# MSP430FR5969 register map
Vendor: msp430gen; File version: v0.4.0-24-gb954137
Registers are 16-bit, read-write, reset 0x0 unless marked. A register's access mark holds for its fields unless they carry their own. Offsets are from the block's base; [hi:lo] are bit positions; {n}, {i} and the like mark numbered series.

## PORT_3_4
Base 0x00000220
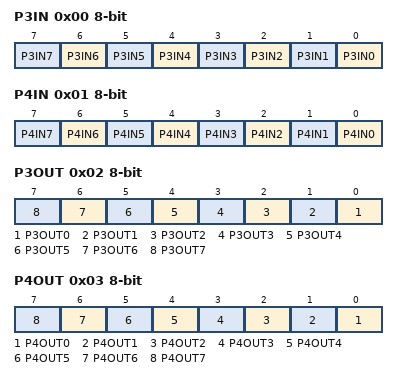
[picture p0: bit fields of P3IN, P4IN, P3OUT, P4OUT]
0x00 P3IN 8-bit — Port 3 Input
  [n] P3IN{n} (n=0..7)
0x01 P4IN 8-bit — Port 4 Input
  [n] P4IN{n} (n=0..7)
0x02 P3OUT 8-bit — Port 3 Output
  [n] P3OUT{n} (n=0..7)
0x03 P4OUT 8-bit — Port 4 Output
  [n] P4OUT{n} (n=0..7)
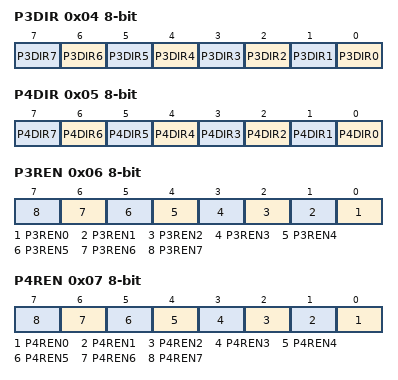
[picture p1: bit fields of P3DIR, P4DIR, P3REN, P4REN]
0x04 P3DIR 8-bit — Port 3 Direction
  [n] P3DIR{n} (n=0..7)
0x05 P4DIR 8-bit — Port 4 Direction
  [n] P4DIR{n} (n=0..7)
0x06 P3REN 8-bit — Port 3 Resistor Enable
  [n] P3REN{n} (n=0..7)
0x07 P4REN 8-bit — Port 4 Resistor Enable
  [n] P4REN{n} (n=0..7)
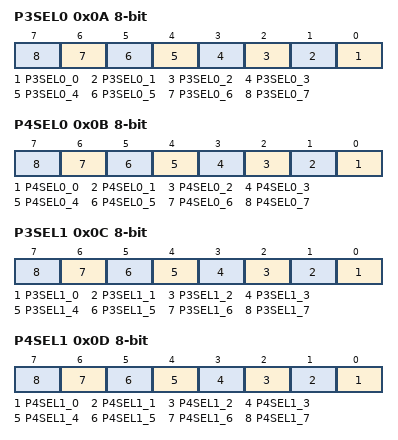
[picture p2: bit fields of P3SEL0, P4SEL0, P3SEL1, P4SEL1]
0x0A P3SEL0 8-bit — Port 3 Selection 0
  [n] P3SEL0_{n} (n=0..7)
0x0B P4SEL0 8-bit — Port 4 Selection 0
  [n] P4SEL0_{n} (n=0..7)
0x0C P3SEL1 8-bit — Port 3 Selection 1
  [n] P3SEL1_{n} (n=0..7)
0x0D P4SEL1 8-bit — Port 4 Selection 1
  [n] P4SEL1_{n} (n=0..7)
0x0E P3IV — Port 3 Interrupt Vector Word
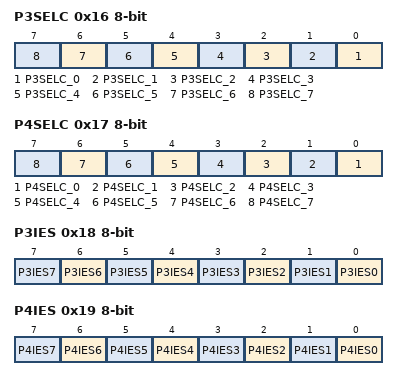
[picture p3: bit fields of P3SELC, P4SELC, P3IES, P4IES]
0x16 P3SELC 8-bit — Port 3 Complement Selection
  [n] P3SELC_{n} (n=0..7)
0x17 P4SELC 8-bit — Port 4 Complement Selection
  [n] P4SELC_{n} (n=0..7)
0x18 P3IES 8-bit — Port 3 Interrupt Edge Select
  [n] P3IES{n} (n=0..7)
0x19 P4IES 8-bit — Port 4 Interrupt Edge Select
  [n] P4IES{n} (n=0..7)
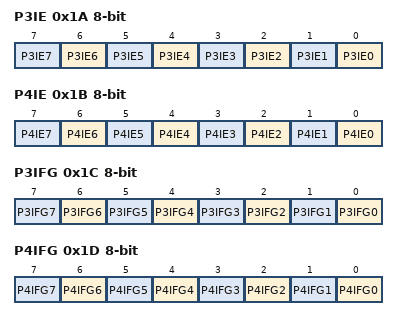
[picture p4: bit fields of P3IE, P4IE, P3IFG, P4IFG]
0x1A P3IE 8-bit — Port 3 Interrupt Enable
  [n] P3IE{n} (n=0..7)
0x1B P4IE 8-bit — Port 4 Interrupt Enable
  [n] P4IE{n} (n=0..7)
0x1C P3IFG 8-bit — Port 3 Interrupt Flag
  [n] P3IFG{n} (n=0..7)
0x1D P4IFG 8-bit — Port 4 Interrupt Flag
  [n] P4IFG{n} (n=0..7)
0x1E P4IV — Port 4 Interrupt Vector Word

## USCI_A0_UART_MODE
Base 0x000005C0
0x00 UCA0CTL1 8-bit — USCI A0 Control Register 1
0x01 UCA0CTL0 8-bit — USCI A0 Control Register 0
0x02 UCA0CTLW1 — USCI A0 Control Word Register 1
  [1:0] UCGLIT — USCI Deglitch Time Bit 1
    {v}=USCI Deglitch time: {v} (v=0..3)
0x06 UCA0BR0 8-bit — USCI A0 Baud Rate 0
0x07 UCA0BR1 8-bit — USCI A0 Baud Rate 1
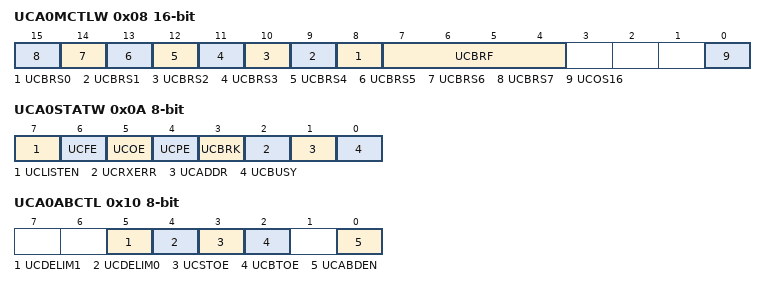
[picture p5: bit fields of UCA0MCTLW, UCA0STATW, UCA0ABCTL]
0x08 UCA0MCTLW — USCI A0 Modulation Control
  [n+8] UCBRS{n} (n=0..7) — USCI Second Stage Modulation Select {n}
  [7:4] UCBRF — USCI First Stage Modulation Select 3
    {v}=USCI First Stage Modulation: {v} (v=0..9); 10=USCI First Stage Modulation: A; 11=USCI First Stage Modulation: B; 12=USCI First Stage Modulation: C; 13=USCI First Stage Modulation: D; 14=USCI First Stage Modulation: E; 15=USCI First Stage Modulation: F
  [0] UCOS16 — USCI 16-times Oversampling enable
0x0A UCA0STATW 8-bit — USCI A0 Status Register
  [7] UCLISTEN — USCI Listen mode
  [6] UCFE — USCI Frame Error Flag
  [5] UCOE — USCI Overrun Error Flag
  [4] UCPE — USCI Parity Error Flag
  [3] UCBRK — USCI Break received
  [2] UCRXERR — USCI RX Error Flag
  [1] UCADDR — USCI Address received Flag
  [0] UCBUSY — USCI Busy Flag
0x0C UCA0RXBUF — USCI A0 Receive Buffer
0x0E UCA0TXBUF — USCI A0 Transmit Buffer
0x10 UCA0ABCTL 8-bit — USCI A0 LIN Control
  [5] UCDELIM1 — Break Sync Delimiter 1
  [4] UCDELIM0 — Break Sync Delimiter 0
  [3] UCSTOE — Sync-Field Timeout error
  [2] UCBTOE — Break Timeout error
  [0] UCABDEN — Auto Baud Rate detect enable
0x12 UCA0IRTCTL 8-bit — USCI A0 IrDA Transmit Control
0x13 UCA0IRRCTL 8-bit — USCI A0 IrDA Receive Control
0x1E UCA0IV — USCI A0 Interrupt Vector Register

## USCI_A0_SPI_MODE
Base 0x000005C0
0x00 UCA0CTL1_SPI 8-bit — USCI A0 Control Register 1
0x01 UCA0CTL0_SPI 8-bit — USCI A0 Control Register 0
0x06 UCA0BR0_SPI 8-bit — USCI A0 Baud Rate 0
0x07 UCA0BR1_SPI 8-bit — USCI A0 Baud Rate 1
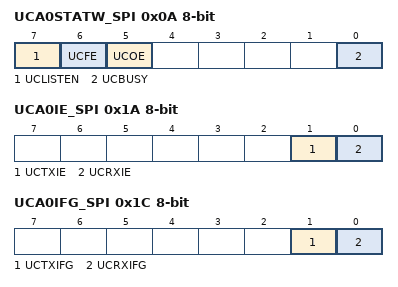
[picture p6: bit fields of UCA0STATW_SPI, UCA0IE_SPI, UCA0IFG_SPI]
0x0A UCA0STATW_SPI 8-bit — USCI A0 Status Register
  [7] UCLISTEN — USCI Listen mode
  [6] UCFE — USCI Frame Error Flag
  [5] UCOE — USCI Overrun Error Flag
  [0] UCBUSY — USCI Busy Flag
0x0C UCA0RXBUF_SPI — USCI A0 Receive Buffer
0x0E UCA0TXBUF_SPI — USCI A0 Transmit Buffer
0x1A UCA0IE_SPI 8-bit — USCI A0 Interrupt Enable Register
  [1] UCTXIE — USCI Transmit Interrupt Enable
  [0] UCRXIE — USCI Receive Interrupt Enable
0x1C UCA0IFG_SPI 8-bit — USCI A0 Interrupt Flags Register
  [1] UCTXIFG — SPI Transmit Interrupt Flag
  [0] UCRXIFG — SPI Receive Interrupt Flag
0x1E UCA0IV_SPI — USCI A0 Interrupt Vector Register
